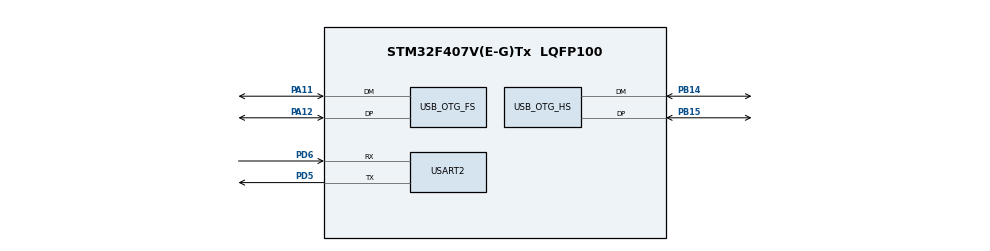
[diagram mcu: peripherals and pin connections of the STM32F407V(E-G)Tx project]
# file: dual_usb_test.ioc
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Mcu.Family=STM32F4
Mcu.Name=STM32F407V(E-G)Tx
Mcu.Package=LQFP100
NVIC.OTG_FS_IRQn=true\:0\:0
NVIC.OTG_HS_IRQn=true\:0\:0
NVIC.PriorityGroup=NVIC_PRIORITYGROUP_0
PA11.Mode=Host_Only
PA11.Signal=USB_OTG_FS_DM
PA12.Mode=Host_Only
PA12.Signal=USB_OTG_FS_DP
PB14.Mode=Host_FS
PB14.Signal=USB_OTG_HS_DM
PB15.Mode=Host_FS
PB15.Signal=USB_OTG_HS_DP
PD5.Mode=Asynchronous
PD5.Signal=USART2_TX
PD6.Mode=Asynchronous
PD6.Signal=USART2_RX
PH0-OSC_IN.Mode=HSE-External-Oscillator
PH0-OSC_IN.Signal=RCC_OSC_IN
PH1-OSC_OUT.Mode=HSE-External-Oscillator
PH1-OSC_OUT.Signal=RCC_OSC_OUT
ProjectManager.TargetToolchain=MDK-ARM 4.73
RCC.APB1CLKDivider=RCC_HCLK_DIV4
RCC.APB2CLKDivider=RCC_HCLK_DIV2
RCC.HSE_VALUE=25000000
RCC.HSI_VALUE=16000000
RCC.LSE_VALUE=32768
RCC.PLLM=25
RCC.PLLN=336
RCC.PLLQ=7
RCC.PLLSource=RCC_PLLSOURCE_HSE
RCC.SYSCLKSource=RCC_SYSCLKSOURCE_PLLCLK
USB_HOST.USBH_HandleTypeDef=hUsbHostHS
USB_HOST.VirtualModeFS=Hid
USB_HOST.VirtualModeHS=Msc
USB_OTG_FS.phy_itface-Host_Only=HCD_PHY_EMBEDDED
USB_OTG_HS.VirtualMode-Host_FS=Host_FS
VP_USB_HOST_VS_USB_HOST_HID_FS.Mode=HID_FS
VP_USB_HOST_VS_USB_HOST_MSC_HS.Mode=MSC_HS

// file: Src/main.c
/**
  ******************************************************************************
  * File Name          : main.c
  * Date               : 17/12/2014 10:56:52
  * Description        : Main program body
  ******************************************************************************
  *
  * COPYRIGHT(c) 2014 STMicroelectronics
  *
  * Redistribution and use in source and binary forms, with or without modification,
  * are permitted provided that the following conditions are met:
  *   1. Redistributions of source code must retain the above copyright notice,
  *      this list of conditions and the following disclaimer.
  *   2. Redistributions in binary form must reproduce the above copyright notice,
  *      this list of conditions and the following disclaimer in the documentation
  *      and/or other materials provided with the distribution.
  *   3. Neither the name of STMicroelectronics nor the names of its contributors
  *      may be used to endorse or promote products derived from this software
  *      without specific prior written permission.
  *
  * THIS SOFTWARE IS PROVIDED BY THE COPYRIGHT HOLDERS AND CONTRIBUTORS "AS IS"
  * AND ANY EXPRESS OR IMPLIED WARRANTIES, INCLUDING, BUT NOT LIMITED TO, THE
  * IMPLIED WARRANTIES OF MERCHANTABILITY AND FITNESS FOR A PARTICULAR PURPOSE ARE
  * DISCLAIMED. IN NO EVENT SHALL THE COPYRIGHT HOLDER OR CONTRIBUTORS BE LIABLE
  * FOR ANY DIRECT, INDIRECT, INCIDENTAL, SPECIAL, EXEMPLARY, OR CONSEQUENTIAL
  * DAMAGES (INCLUDING, BUT NOT LIMITED TO, PROCUREMENT OF SUBSTITUTE GOODS OR
  * SERVICES; LOSS OF USE, DATA, OR PROFITS; OR BUSINESS INTERRUPTION) HOWEVER
  * CAUSED AND ON ANY THEORY OF LIABILITY, WHETHER IN CONTRACT, STRICT LIABILITY,
  * OR TORT (INCLUDING NEGLIGENCE OR OTHERWISE) ARISING IN ANY WAY OUT OF THE USE
  * OF THIS SOFTWARE, EVEN IF ADVISED OF THE POSSIBILITY OF SUCH DAMAGE.
  *
  ******************************************************************************
  */

#include "stm32f4xx_hal.h"
#include "usart.h"
#include "usb_host.h"
#include "gpio.h"

void SystemClock_Config(void);
void MX_USB_HOST_Process(void);

int main(void)
{

  /* MCU Configuration----------------------------------------------------------*/

  /* Reset of all peripherals, Initializes the Flash interface and the Systick. */
  HAL_Init();

  /* Configure the system clock */
  SystemClock_Config();

  /* System interrupt init*/
  /* Sets the priority grouping field */
  HAL_NVIC_SetPriorityGrouping(NVIC_PRIORITYGROUP_0);
  HAL_NVIC_SetPriority(SysTick_IRQn, 0, 0);

  /* Initialize all configured peripherals */
  MX_GPIO_Init();
  MX_USART2_UART_Init();
  MX_USB_HOST_Init();

  /* USER CODE BEGIN 3 */
  /* Infinite loop */
  while (1)
  {
//	printf("i am wrong\r\n");
    MX_USB_HOST_Process();

  }
  /* USER CODE END 3 */

}

/** System Clock Configuration
*/
void SystemClock_Config(void)
{

  RCC_ClkInitTypeDef RCC_ClkInitStruct;
  RCC_OscInitTypeDef RCC_OscInitStruct;

  __PWR_CLK_ENABLE();

  __HAL_PWR_VOLTAGESCALING_CONFIG(PWR_REGULATOR_VOLTAGE_SCALE1);

  RCC_OscInitStruct.OscillatorType = RCC_OSCILLATORTYPE_HSE;
  RCC_OscInitStruct.HSEState = RCC_HSE_ON;
  RCC_OscInitStruct.PLL.PLLState = RCC_PLL_ON;
  RCC_OscInitStruct.PLL.PLLSource = RCC_PLLSOURCE_HSE;
  RCC_OscInitStruct.PLL.PLLM = 25;
  RCC_OscInitStruct.PLL.PLLN = 336;
  RCC_OscInitStruct.PLL.PLLP = RCC_PLLP_DIV2;
  RCC_OscInitStruct.PLL.PLLQ = 7;
  HAL_RCC_OscConfig(&RCC_OscInitStruct);

  RCC_ClkInitStruct.ClockType = RCC_CLOCKTYPE_SYSCLK|RCC_CLOCKTYPE_PCLK1
                              |RCC_CLOCKTYPE_PCLK2;
  RCC_ClkInitStruct.SYSCLKSource = RCC_SYSCLKSOURCE_PLLCLK;
  RCC_ClkInitStruct.AHBCLKDivider = RCC_SYSCLK_DIV1;
  RCC_ClkInitStruct.APB1CLKDivider = RCC_HCLK_DIV4;
  RCC_ClkInitStruct.APB2CLKDivider = RCC_HCLK_DIV2;
  HAL_RCC_ClockConfig(&RCC_ClkInitStruct, FLASH_LATENCY_5);

}

/************************ (C) COPYRIGHT STMicroelectronics *****END OF FILE****/
